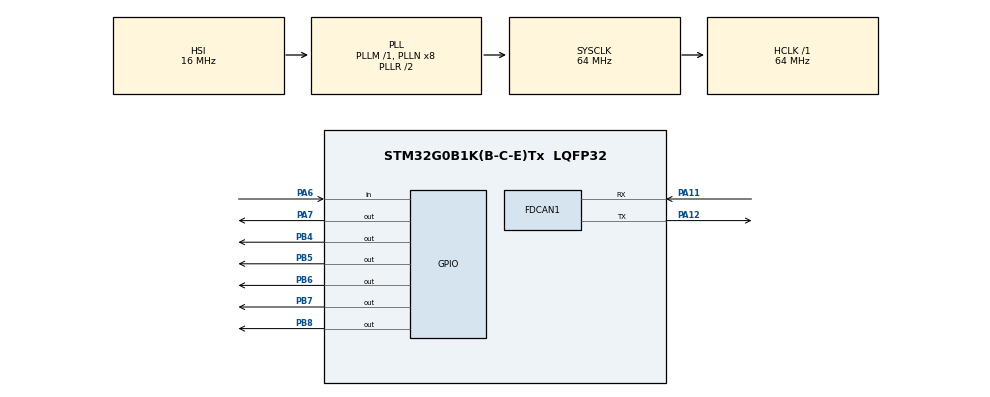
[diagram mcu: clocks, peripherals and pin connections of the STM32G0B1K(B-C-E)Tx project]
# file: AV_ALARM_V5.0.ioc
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FDCAN1.CalculateBaudRateNominal=500000
FDCAN1.CalculateTimeBitNominal=2000
FDCAN1.CalculateTimeQuantumNominal=125.0
FDCAN1.DataSyncJumpWidth=8
FDCAN1.DataTimeSeg1=9
FDCAN1.DataTimeSeg2=6
FDCAN1.NominalPrescaler=8
FDCAN1.NominalTimeSeg1=9
FDCAN1.NominalTimeSeg2=6
Mcu.Family=STM32G0
Mcu.Name=STM32G0B1K(B-C-E)Tx
Mcu.Package=LQFP32
NVIC.TIM16_FDCAN_IT0_IRQn=true\:0\:0\:false\:false\:true\:true\:true\:true
NVIC.TIM17_FDCAN_IT1_IRQn=true\:0\:0\:false\:false\:true\:true\:true\:true
NVIC.TIM2_IRQn=true\:0\:0\:false\:false\:true\:true\:true\:true
PA11\ [PA9].Mode=FDCAN_Activate
PA11\ [PA9].Signal=FDCAN1_RX
PA12\ [PA10].Mode=FDCAN_Activate
PA12\ [PA10].Signal=FDCAN1_TX
PA6.Signal=GPIO_Input
PA7.Signal=GPIO_Output
PB4.Signal=GPIO_Output
PB5.Signal=GPIO_Output
PB6.Signal=GPIO_Output
PB7.Signal=GPIO_Output
PB8.Signal=GPIO_Output
ProjectManager.HeapSize=0x200
ProjectManager.StackSize=0x400
ProjectManager.TargetToolchain=STM32CubeIDE
RCC.ADCFreq_Value=64000000
RCC.AHBFreq_Value=64000000
RCC.CortexFreq_Value=64000000
RCC.EXTERNAL_CLOCK_VALUE=48000
RCC.HCLKFreq_Value=64000000
RCC.HSE_VALUE=8000000
RCC.HSI48_VALUE=48000000
RCC.HSI_VALUE=16000000
RCC.LSE_VALUE=32768
RCC.SYSCLKFreq_VALUE=64000000
RCC.SYSCLKSource=RCC_SYSCLKSOURCE_PLLCLK
RCC.USBFreq_Value=48000000
RCC.VCOOutputFreq_Value=128000000
TIM2.Period=1
TIM2.Prescaler=64000
VP_TIM2_VS_ClockSourceINT.Mode=Internal
board=custom

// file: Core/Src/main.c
/* USER CODE BEGIN Header */
/**
  ******************************************************************************
  * @file           : main.c
  * @brief          : Main program body
  ******************************************************************************
  * @attention
  *
  * Copyright (c) 2023 STMicroelectronics.
  * All rights reserved.
  *
  * This software is licensed under terms that can be found in the LICENSE file
  * in the root directory of this software component.
  * If no LICENSE file comes with this software, it is provided AS-IS.
  *
  ******************************************************************************
  */
/* USER CODE END Header */
#include "main.h"

/* USER CODE BEGIN PM */

void CaptureData_Battery(void);
void CaptureData_Fault(void);
void battery_indicator(void);
void Capture_Current(void);
/* USER CODE END PM */

FDCAN_HandleTypeDef hfdcan1;

TIM_HandleTypeDef htim2;

void SystemClock_Config(void);
static void MX_GPIO_Init(void);
static void MX_FDCAN1_Init(void);
static void MX_TIM2_Init(void);
/* USER CODE BEGIN PFP */
void FDCAN_Config(void);
/* USER CODE END PFP */

int main(void)
{
  /* USER CODE BEGIN 1 */
//FDCAN_HandleTypeDef hfdcan1;
  /* USER CODE END 1 */

  /* MCU Configuration--------------------------------------------------------*/

  /* Reset of all peripherals, Initializes the Flash interface and the Systick. */
  HAL_Init();

  /* Configure the system clock */
  SystemClock_Config();

  /* Initialize all configured peripherals */
  MX_GPIO_Init();
  MX_FDCAN1_Init();
  MX_TIM2_Init();

  /* Infinite loop */
  while (1)
  {
	  ButtonFunc();
  }
}

void SystemClock_Config(void)
{
  RCC_OscInitTypeDef RCC_OscInitStruct = {0};
  RCC_ClkInitTypeDef RCC_ClkInitStruct = {0};

  /** Configure the main internal regulator output voltage
  */
  HAL_PWREx_ControlVoltageScaling(PWR_REGULATOR_VOLTAGE_SCALE1);

  /** Initializes the RCC Oscillators according to the specified parameters
  * in the RCC_OscInitTypeDef structure.
  */
  RCC_OscInitStruct.OscillatorType = RCC_OSCILLATORTYPE_HSI;
  RCC_OscInitStruct.HSIState = RCC_HSI_ON;
  RCC_OscInitStruct.HSIDiv = RCC_HSI_DIV1;
  RCC_OscInitStruct.HSICalibrationValue = RCC_HSICALIBRATION_DEFAULT;
  RCC_OscInitStruct.PLL.PLLState = RCC_PLL_ON;
  RCC_OscInitStruct.PLL.PLLSource = RCC_PLLSOURCE_HSI;
  RCC_OscInitStruct.PLL.PLLM = RCC_PLLM_DIV1;
  RCC_OscInitStruct.PLL.PLLN = 8;
  RCC_OscInitStruct.PLL.PLLP = RCC_PLLP_DIV2;
  RCC_OscInitStruct.PLL.PLLQ = RCC_PLLQ_DIV2;
  RCC_OscInitStruct.PLL.PLLR = RCC_PLLR_DIV2;
  if (HAL_RCC_OscConfig(&RCC_OscInitStruct) != HAL_OK)
  {
    Error_Handler();
  }

  /** Initializes the CPU, AHB and APB buses clocks
  */
  RCC_ClkInitStruct.ClockType = RCC_CLOCKTYPE_HCLK|RCC_CLOCKTYPE_SYSCLK
                              |RCC_CLOCKTYPE_PCLK1;
  RCC_ClkInitStruct.SYSCLKSource = RCC_SYSCLKSOURCE_PLLCLK;
  RCC_ClkInitStruct.AHBCLKDivider = RCC_SYSCLK_DIV1;
  RCC_ClkInitStruct.APB1CLKDivider = RCC_HCLK_DIV1;

  if (HAL_RCC_ClockConfig(&RCC_ClkInitStruct, FLASH_LATENCY_2) != HAL_OK)
  {
    Error_Handler();
  }
}

static void MX_FDCAN1_Init(void)
{

  hfdcan1.Instance = FDCAN1;
  hfdcan1.Init.ClockDivider = FDCAN_CLOCK_DIV1;
  hfdcan1.Init.FrameFormat = FDCAN_FRAME_CLASSIC;
  hfdcan1.Init.Mode = FDCAN_MODE_NORMAL;
  hfdcan1.Init.AutoRetransmission = DISABLE;
  hfdcan1.Init.TransmitPause = DISABLE;
  hfdcan1.Init.ProtocolException = DISABLE;
  hfdcan1.Init.NominalPrescaler = 8;
  hfdcan1.Init.NominalSyncJumpWidth = 1;
  hfdcan1.Init.NominalTimeSeg1 = 9;
  hfdcan1.Init.NominalTimeSeg2 = 6;
  hfdcan1.Init.DataPrescaler = 1;
  hfdcan1.Init.DataSyncJumpWidth = 8;
  hfdcan1.Init.DataTimeSeg1 = 9;
  hfdcan1.Init.DataTimeSeg2 = 6;
  hfdcan1.Init.StdFiltersNbr = 0;
  hfdcan1.Init.ExtFiltersNbr = 0;
  hfdcan1.Init.TxFifoQueueMode = FDCAN_TX_FIFO_OPERATION;
  if (HAL_FDCAN_Init(&hfdcan1) != HAL_OK)
  {
    Error_Handler();
  }

}

static void MX_TIM2_Init(void)
{

  TIM_ClockConfigTypeDef sClockSourceConfig = {0};
  TIM_MasterConfigTypeDef sMasterConfig = {0};

  htim2.Instance = TIM2;
  htim2.Init.Prescaler = 64000;
  htim2.Init.CounterMode = TIM_COUNTERMODE_UP;
  htim2.Init.Period = 1;
  htim2.Init.ClockDivision = TIM_CLOCKDIVISION_DIV1;
  htim2.Init.AutoReloadPreload = TIM_AUTORELOAD_PRELOAD_DISABLE;
  if (HAL_TIM_Base_Init(&htim2) != HAL_OK)
  {
    Error_Handler();
  }
  sClockSourceConfig.ClockSource = TIM_CLOCKSOURCE_INTERNAL;
  if (HAL_TIM_ConfigClockSource(&htim2, &sClockSourceConfig) != HAL_OK)
  {
    Error_Handler();
  }
  sMasterConfig.MasterOutputTrigger = TIM_TRGO_RESET;
  sMasterConfig.MasterSlaveMode = TIM_MASTERSLAVEMODE_DISABLE;
  if (HAL_TIMEx_MasterConfigSynchronization(&htim2, &sMasterConfig) != HAL_OK)
  {
    Error_Handler();
  }

}

static void MX_GPIO_Init(void)
{
  GPIO_InitTypeDef GPIO_InitStruct = {0};

  /* GPIO Ports Clock Enable */
  __HAL_RCC_GPIOA_CLK_ENABLE();
  __HAL_RCC_GPIOB_CLK_ENABLE();

  /*Configure GPIO pin Output Level */
  HAL_GPIO_WritePin(GPIOA, GPIO_PIN_7, GPIO_PIN_RESET);

  /*Configure GPIO pin Output Level */
  HAL_GPIO_WritePin(GPIOB, GPIO_PIN_4|GPIO_PIN_5|GPIO_PIN_6|GPIO_PIN_7
                          |GPIO_PIN_8, GPIO_PIN_RESET);

  /*Configure GPIO pin : PA6 */
  GPIO_InitStruct.Pin = GPIO_PIN_6;
  GPIO_InitStruct.Mode = GPIO_MODE_INPUT;
  GPIO_InitStruct.Pull = GPIO_NOPULL;
  HAL_GPIO_Init(GPIOA, &GPIO_InitStruct);

  /*Configure GPIO pin : PA7 */
  GPIO_InitStruct.Pin = GPIO_PIN_7;
  GPIO_InitStruct.Mode = GPIO_MODE_OUTPUT_PP;
  GPIO_InitStruct.Pull = GPIO_NOPULL;
  GPIO_InitStruct.Speed = GPIO_SPEED_FREQ_LOW;
  HAL_GPIO_Init(GPIOA, &GPIO_InitStruct);

  /*Configure GPIO pins : PB4 PB5 PB6 PB7
                           PB8 */
  GPIO_InitStruct.Pin = GPIO_PIN_4|GPIO_PIN_5|GPIO_PIN_6|GPIO_PIN_7
                          |GPIO_PIN_8;
  GPIO_InitStruct.Mode = GPIO_MODE_OUTPUT_PP;
  GPIO_InitStruct.Pull = GPIO_NOPULL;
  GPIO_InitStruct.Speed = GPIO_SPEED_FREQ_LOW;
  HAL_GPIO_Init(GPIOB, &GPIO_InitStruct);

}

void Error_Handler(void)
{
  __disable_irq();
  while (1)
  {
  }
}
